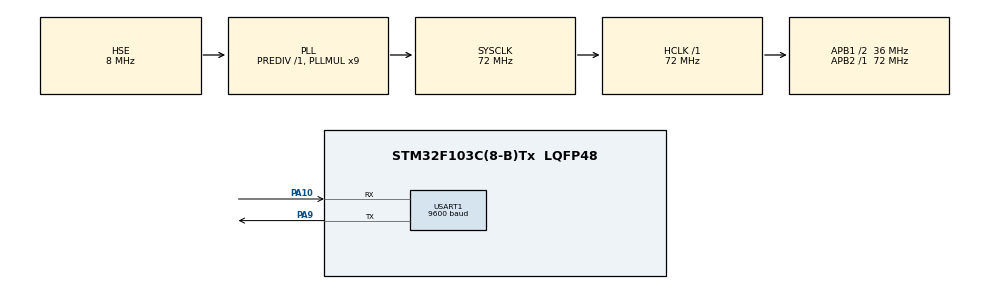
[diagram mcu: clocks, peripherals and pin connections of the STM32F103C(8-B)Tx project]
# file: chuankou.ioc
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Dma.Request0=USART1_TX
Dma.USART1_TX.0.Direction=DMA_MEMORY_TO_PERIPH
Dma.USART1_TX.0.Instance=DMA1_Channel4
Dma.USART1_TX.0.MemDataAlignment=DMA_MDATAALIGN_BYTE
Dma.USART1_TX.0.MemInc=DMA_MINC_ENABLE
Dma.USART1_TX.0.Mode=DMA_NORMAL
Dma.USART1_TX.0.PeriphDataAlignment=DMA_PDATAALIGN_BYTE
Dma.USART1_TX.0.PeriphInc=DMA_PINC_DISABLE
Dma.USART1_TX.0.Priority=DMA_PRIORITY_LOW
Mcu.Family=STM32F1
Mcu.Name=STM32F103C(8-B)Tx
Mcu.Package=LQFP48
NVIC.DMA1_Channel4_IRQn=true\:0\:0\:false\:false\:true\:false\:true\:true
NVIC.PriorityGroup=NVIC_PRIORITYGROUP_4
NVIC.TIM2_IRQn=true\:0\:0\:false\:false\:true\:true\:true\:true
PA10.Mode=Asynchronous
PA10.Signal=USART1_RX
PA13.Mode=Serial_Wire
PA13.Signal=SYS_JTMS-SWDIO
PA14.Mode=Serial_Wire
PA14.Signal=SYS_JTCK-SWCLK
PA9.Mode=Asynchronous
PA9.Signal=USART1_TX
PD0-OSC_IN.Mode=HSE-External-Oscillator
PD0-OSC_IN.Signal=RCC_OSC_IN
PD1-OSC_OUT.Mode=HSE-External-Oscillator
PD1-OSC_OUT.Signal=RCC_OSC_OUT
ProjectManager.HeapSize=0x200
ProjectManager.StackSize=0x400
ProjectManager.TargetToolchain=MDK-ARM V5.32
RCC.AHBFreq_Value=72000000
RCC.APB1CLKDivider=RCC_HCLK_DIV2
RCC.APB1Freq_Value=36000000
RCC.APB1TimFreq_Value=72000000
RCC.APB2Freq_Value=72000000
RCC.APB2TimFreq_Value=72000000
RCC.HCLKFreq_Value=72000000
RCC.PLLMUL=RCC_PLL_MUL9
RCC.PLLSourceVirtual=RCC_PLLSOURCE_HSE
RCC.SYSCLKFreq_VALUE=72000000
RCC.SYSCLKSource=RCC_SYSCLKSOURCE_PLLCLK
RCC.USBFreq_Value=72000000
TIM2.Period=1000-1
TIM2.Prescaler=720-1
USART1.BaudRate=9600
USART1.VirtualMode=VM_ASYNC
VP_TIM2_VS_ClockSourceINT.Mode=Internal
board=custom

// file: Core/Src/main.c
/* USER CODE BEGIN Header */
/**
  ******************************************************************************
  * @file           : main.c
  * @brief          : Main program body
  ******************************************************************************
  * @attention
  *
  * Copyright (c) 2025 STMicroelectronics.
  * All rights reserved.
  *
  * This software is licensed under terms that can be found in the LICENSE file
  * in the root directory of this software component.
  * If no LICENSE file comes with this software, it is provided AS-IS.
  *
  ******************************************************************************
  */
/* USER CODE END Header */
#include "main.h"
#include "dma.h"
#include "tim.h"
#include "usart.h"
#include "gpio.h"

/* USER CODE BEGIN Includes */
#include <stdio.h>
#include <string.h>
#include <math.h>
#define CH_COUNT 1
/* USER CODE END Includes */

/* USER CODE BEGIN PV */
static float depth = 0.0f;
static float v = 0.0f;
static float a = 0.0f;
static const float m = 10.0f;
static const float kv = 1.0f;
static const float f = 1.0f;
static const float target = 20.0f;
static float t = 0.0f;

static float Kp = 12.0f;
static float Ki = 0.3f;
static float Kd = 8.0f;

static float error, integral = 0.0f, last_error = 0.0f, derivative;
struct Frame {
    float fdata[CH_COUNT];
    unsigned char tail[4];
};
/* USER CODE END PV */

void SystemClock_Config(void);

/* USER CODE BEGIN 0 */
void HAL_TIM_PeriodElapsedCallback(TIM_HandleTypeDef *htim)
{
//	error = target - depth;
//	integral += error * 0.1f;
//	derivative = (error - last_error) / 0.1f;

	float F ;

//	if (F < 0) F = 0;
//	if (F > 50) F = 50;

//	a = (F - kv * v - f) / m;
//	v += a * 0.1f;
//	depth += v * 0.1f;

//	last_error = error;
//	 t+=0.1;

	 error = target - depth;
    float dt = 0.1f;

    derivative = (error - last_error) / dt;

    float integral_temp = integral;
    float error_threshold = 5.0f;

    if (fabs(error) < error_threshold) {
        if (F < 50 && F > 0) {
            integral += error * dt;
        }
    } else {
        integral = integral_temp;
    }

    F = Kp * error + Ki * integral + Kd * derivative;

    if (F < 0) F = 0;
    if (F > 50) F = 50;

    a = (F - kv * v - f) / m;
    v += a * dt;
    depth += v * dt;

    last_error = error;
    t += dt;
    struct Frame frame;
    frame.fdata[0] = depth;
    frame.tail[0] = 0x00;
    frame.tail[1] = 0x00;
    frame.tail[2] = 0x80;
    frame.tail[3] = 0x7f;

    HAL_UART_Transmit(&huart1, (uint8_t*)frame.fdata, sizeof(float) * CH_COUNT, 100);
    HAL_UART_Transmit(&huart1, frame.tail, 4, 100);

}

/* USER CODE END 0 */

int main(void)
{

  /* MCU Configuration--------------------------------------------------------*/

  /* Reset of all peripherals, Initializes the Flash interface and the Systick. */
  HAL_Init();

  /* Configure the system clock */
  SystemClock_Config();

  /* Initialize all configured peripherals */
  MX_GPIO_Init();
  MX_DMA_Init();
  MX_USART1_UART_Init();
  MX_TIM2_Init();
  /* USER CODE BEGIN 2 */
  HAL_TIM_Base_Start_IT(&htim2);
  /* USER CODE END 2 */

  /* Infinite loop */
  while (1)
  {

  }
}

void SystemClock_Config(void)
{
  RCC_OscInitTypeDef RCC_OscInitStruct = {0};
  RCC_ClkInitTypeDef RCC_ClkInitStruct = {0};

  /** Initializes the RCC Oscillators according to the specified parameters
  * in the RCC_OscInitTypeDef structure.
  */
  RCC_OscInitStruct.OscillatorType = RCC_OSCILLATORTYPE_HSE;
  RCC_OscInitStruct.HSEState = RCC_HSE_ON;
  RCC_OscInitStruct.HSEPredivValue = RCC_HSE_PREDIV_DIV1;
  RCC_OscInitStruct.HSIState = RCC_HSI_ON;
  RCC_OscInitStruct.PLL.PLLState = RCC_PLL_ON;
  RCC_OscInitStruct.PLL.PLLSource = RCC_PLLSOURCE_HSE;
  RCC_OscInitStruct.PLL.PLLMUL = RCC_PLL_MUL9;
  if (HAL_RCC_OscConfig(&RCC_OscInitStruct) != HAL_OK)
  {
    Error_Handler();
  }

  /** Initializes the CPU, AHB and APB buses clocks
  */
  RCC_ClkInitStruct.ClockType = RCC_CLOCKTYPE_HCLK|RCC_CLOCKTYPE_SYSCLK
                              |RCC_CLOCKTYPE_PCLK1|RCC_CLOCKTYPE_PCLK2;
  RCC_ClkInitStruct.SYSCLKSource = RCC_SYSCLKSOURCE_PLLCLK;
  RCC_ClkInitStruct.AHBCLKDivider = RCC_SYSCLK_DIV1;
  RCC_ClkInitStruct.APB1CLKDivider = RCC_HCLK_DIV2;
  RCC_ClkInitStruct.APB2CLKDivider = RCC_HCLK_DIV1;

  if (HAL_RCC_ClockConfig(&RCC_ClkInitStruct, FLASH_LATENCY_2) != HAL_OK)
  {
    Error_Handler();
  }
}

void Error_Handler(void)
{
  __disable_irq();
  while (1)
  {
  }
}
